# MKL28Z7 register map
Vendor: Freescale Semiconductor, Inc.; Series: Kinetis_L; File version: 1.6
CPU: CM0PLUS r0p0, little endian, no MPU, no FPU, VTOR, 2 interrupt priority bits
Registers are 32-bit, read-write, reset 0x0 unless marked. A register's access mark holds for its fields unless they carry their own. Offsets are from the block's base; [hi:lo] are bit positions; {n}, {i} and the like mark numbered series; 'fields as' and 'values as' point back to an identical list.

## TRGMUX0
Base 0x40027000
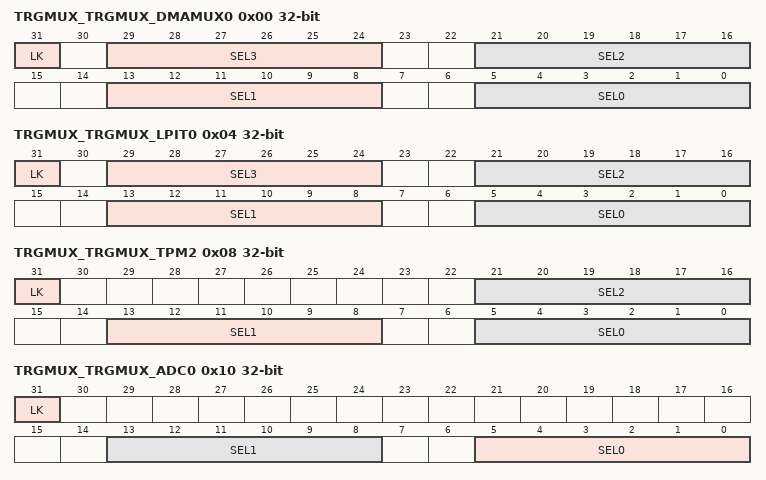
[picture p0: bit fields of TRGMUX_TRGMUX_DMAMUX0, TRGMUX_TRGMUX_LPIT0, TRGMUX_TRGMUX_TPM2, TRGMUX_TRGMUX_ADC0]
0x00 TRGMUX_TRGMUX_DMAMUX0 — TRGMUX TRGCFG Register
  [31] LK — Enable
    0=Register can be written; 1=Register cannot be written until the next system Reset
  [8n+5:8n] SEL{n} (n=0..3) — Trigger MUX Input {n} Source Select
0x04 TRGMUX_TRGMUX_LPIT0 — TRGMUX TRGCFG Register
  fields as TRGMUX_TRGMUX_DMAMUX0
0x08 TRGMUX_TRGMUX_TPM2 — TRGMUX TRGCFG Register
  [31] LK — Enable
    values as TRGMUX_TRGMUX_DMAMUX0.LK
  [21:16] SEL2 — Trigger MUX Input 2 Source Select
  [13:8] SEL1 — Trigger MUX Input 1 Source Select
  [5:0] SEL0 — Trigger MUX Input 0 Source Select
0x10 TRGMUX_TRGMUX_ADC0 — TRGMUX TRGCFG Register
  [31] LK — Enable
    values as TRGMUX_TRGMUX_DMAMUX0.LK
  [13:8] SEL1 — Trigger MUX Input 1 Source Select
  [5:0] SEL0 — Trigger MUX Input 0 Source Select
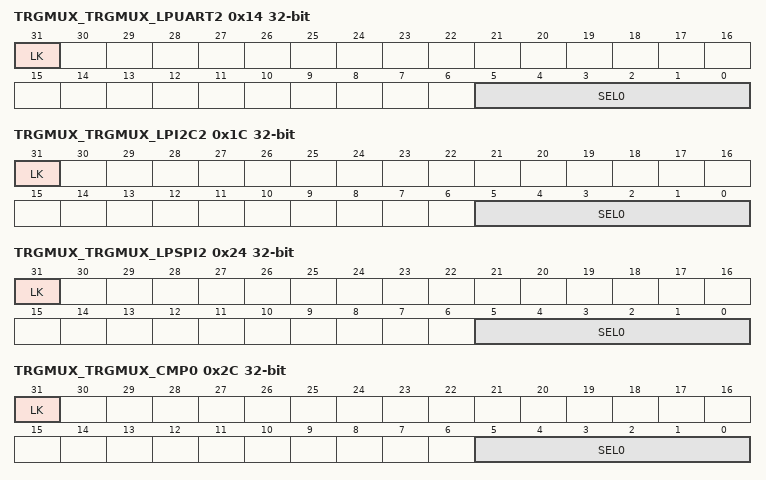
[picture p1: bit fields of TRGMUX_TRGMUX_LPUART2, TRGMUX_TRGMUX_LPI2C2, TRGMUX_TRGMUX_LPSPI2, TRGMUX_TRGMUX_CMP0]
0x14 TRGMUX_TRGMUX_LPUART2 — TRGMUX TRGCFG Register
  [31] LK — Enable
    values as TRGMUX_TRGMUX_DMAMUX0.LK
  [5:0] SEL0 — Trigger MUX Input 0 Source Select
0x1C TRGMUX_TRGMUX_LPI2C2 — TRGMUX TRGCFG Register
  fields as TRGMUX_TRGMUX_LPUART2
0x24 TRGMUX_TRGMUX_LPSPI2 — TRGMUX TRGCFG Register
  fields as TRGMUX_TRGMUX_LPUART2
0x2C TRGMUX_TRGMUX_CMP0 — TRGMUX TRGCFG Register
  fields as TRGMUX_TRGMUX_LPUART2
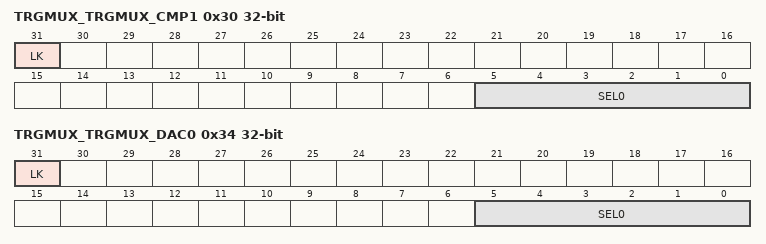
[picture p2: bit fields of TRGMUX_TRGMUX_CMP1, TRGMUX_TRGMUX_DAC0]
0x30 TRGMUX_TRGMUX_CMP1 — TRGMUX TRGCFG Register
  fields as TRGMUX_TRGMUX_LPUART2
0x34 TRGMUX_TRGMUX_DAC0 — TRGMUX TRGCFG Register
  fields as TRGMUX_TRGMUX_LPUART2

## LPTMR0 — Low Power Timer
Base 0x40034000; register names take the prefix LPTMR0_
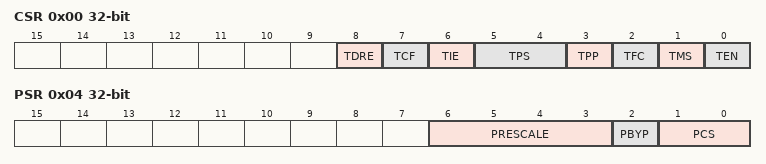
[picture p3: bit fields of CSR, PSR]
0x00 CSR — Low Power Timer Control Status Register
  [8] TDRE — Timer DMA Request Enable
    0=Timer DMA Request disabled; 1=Timer DMA Request enabled
  [7] TCF — Timer Compare Flag
    0=The value of CNR is not equal to CMR and increments; 1=The value of CNR is equal to CMR and increments
  [6] TIE — Timer Interrupt Enable
    0=Timer interrupt disabled; 1=Timer interrupt enabled
  [5:4] TPS — Timer Pin Select
    {v}=Pulse counter input {v} is selected (v=0..3)
  [3] TPP — Timer Pin Polarity
    0=Pulse Counter input source is active-high, and the CNR will increment on the rising-edge; 1=Pulse Counter input source is active-low, and the CNR will increment on the falling-edge
  [2] TFC — Timer Free-Running Counter
    0=CNR is reset whenever TCF is set; 1=CNR is reset on overflow
  [1] TMS — Timer Mode Select
    0=Time Counter mode; 1=Pulse Counter mode
  [0] TEN — Timer Enable
    0=LPTMR is disabled and internal logic is reset; 1=LPTMR is enabled
0x04 PSR — Low Power Timer Prescale Register
  [6:3] PRESCALE — Prescale Value
    0=Prescaler divides the prescaler clock by 2; glitch filter does not support this configuration; 1=Prescaler divides the prescaler clock by 4; glitch filter recognizes change on input pin after 2 rising clock edges; 2=Prescaler divides the prescaler clock by 8; glitch filter recognizes change on input pin after 4 rising clock edges; 3=Prescaler divides the prescaler clock by 16; glitch filter recognizes change on input pin after 8 rising clock edges; 4=Prescaler divides the prescaler clock by 32; glitch filter recognizes change on input pin after 16 rising clock edges; 5=Prescaler divides the prescaler clock by 64; glitch filter recognizes change on input pin after 32 rising clock edges; 6=Prescaler divides the prescaler clock by 128; glitch filter recognizes change on input pin after 64 rising clock edges; 7=Prescaler divides the prescaler clock by 256; glitch filter recognizes change on input pin after 128 rising clock edges; 8=Prescaler divides the prescaler clock by 512; glitch filter recognizes change on input pin after 256 rising clock edges; 9=Prescaler divides the prescaler clock by 1024; glitch filter recognizes change on input pin after 512 rising clock edges; 10=Prescaler divides the prescaler clock by 2048; glitch filter recognizes change on input pin after 1024 rising clock edges; 11=Prescaler divides the prescaler clock by 4096; glitch filter recognizes change on input pin after 2048 rising clock edges; 12=Prescaler divides the prescaler clock by 8192; glitch filter recognizes change on input pin after 4096 rising clock edges; 13=Prescaler divides the prescaler clock by 16,384; glitch filter recognizes change on input pin after 8192 rising clock edges; 14=Prescaler divides the prescaler clock by 32,768; glitch filter recognizes change on input pin after 16,384 rising clock edges; 15=Prescaler divides the prescaler clock by 65,536; glitch filter recognizes change on input pin after 32,768 rising clock edges
  [2] PBYP — Prescaler Bypass
    0=Prescaler/glitch filter is enabled; 1=Prescaler/glitch filter is bypassed
  [1:0] PCS — Prescaler Clock Select
    {v}=Prescaler/glitch filter clock {v} selected (v=0..3)
0x08 CMR — Low Power Timer Compare Register
  [15:0] COMPARE — Compare Value
0x0C CNR — Low Power Timer Counter Register
  [15:0] COUNTER — Counter Value

## LPTMR1 — Low Power Timer
Base 0x400B5000; register names take the prefix LPTMR1_
Registers as LPTMR0.

## Notices in the file
Redistribution and use in source and binary forms, with or without modification,
are permitted provided that the following conditions are met:
o Redistributions of source code must retain the above copyright notice, this list
of conditions and the following disclaimer.
o Redistributions in binary form must reproduce the above copyright notice, this
list of conditions and the following disclaimer in the documentation and/or
other materials provided with the distribution.
o Neither the name of Freescale Semiconductor, Inc. nor the names of its
contributors may be used to endorse or promote products derived from this
software without specific prior written permission.
THIS SOFTWARE IS PROVIDED BY THE COPYRIGHT HOLDERS AND CONTRIBUTORS "AS IS" AND
ANY EXPRESS OR IMPLIED WARRANTIES, INCLUDING, BUT NOT LIMITED TO, THE IMPLIED
WARRANTIES OF MERCHANTABILITY AND FITNESS FOR A PARTICULAR PURPOSE ARE
DISCLAIMED. IN NO EVENT SHALL THE COPYRIGHT HOLDER OR CONTRIBUTORS BE LIABLE FOR
ANY DIRECT, INDIRECT, INCIDENTAL, SPECIAL, EXEMPLARY, OR CONSEQUENTIAL DAMAGES
(INCLUDING, BUT NOT LIMITED TO, PROCUREMENT OF SUBSTITUTE GOODS OR SERVICES;
LOSS OF USE, DATA, OR PROFITS; OR BUSINESS INTERRUPTION) HOWEVER CAUSED AND ON
ANY THEORY OF LIABILITY, WHETHER IN CONTRACT, STRICT LIABILITY, OR TORT
(INCLUDING NEGLIGENCE OR OTHERWISE) ARISING IN ANY WAY OUT OF THE USE OF THIS
SOFTWARE, EVEN IF ADVISED OF THE POSSIBILITY OF SUCH DAMAGE.
